AUTOSAR XML (schema 4-3-0)
package /DBCImport/CANTP
  can tp config CanTpConfig_LOCALCAN: communication-cluster=LOCALCAN, can-tp-ecu=SCM
    can tp channel CanTpChannel1: channel-id=1, channel-mode=HALF-DUPLEX-MODE
    tp-connections:
      addressing-format=STANDARD, can-tp-channel=CanTpChannel1, data-pdu=NPdu_LOCALCAN_TP_BDC_C_WPC, flow-control-pdu=NPdu_LOCALCAN_TP_WPC_C_BDC, max-block-size=0, padding-activation=true, ta-type=PHYSICAL, tp-sdu=ISignalIPdu_LOCALCAN_TP_BDC_C_WPC
      addressing-format=STANDARD, can-tp-channel=CanTpChannel1, data-pdu=NPdu_LOCALCAN_TP_WPC_C_BDC, flow-control-pdu=NPdu_LOCALCAN_TP_BDC_C_WPC, max-block-size=0, padding-activation=true, ta-type=PHYSICAL, tp-sdu=ISignalIPdu_LOCALCAN_TP_WPC_C_BDC
    can tp node SCM: connector=Conn_SCM_LOCALCAN
package /DBCImport/SWCComposition
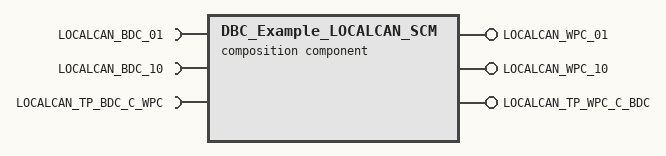
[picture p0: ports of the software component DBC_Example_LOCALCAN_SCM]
  composition sw component type DBC_Example_LOCALCAN_SCM
    provide port LOCALCAN_WPC_01: provided-interface=LOCALCAN_WPC_01
    provide port LOCALCAN_WPC_10: provided-interface=LOCALCAN_WPC_10
    provide port LOCALCAN_TP_WPC_C_BDC: provided-interface=LOCALCAN_TP_WPC_C_BDC
    require port LOCALCAN_BDC_01: required-interface=LOCALCAN_BDC_01
    require port LOCALCAN_BDC_10: required-interface=LOCALCAN_BDC_10
    require port LOCALCAN_TP_BDC_C_WPC: required-interface=LOCALCAN_TP_BDC_C_WPC
package /DBCImport/CLUSTERS
  can cluster LOCALCAN: baudrate=500000, protocol-name=CAN, speed=500
    can physical channel LOCALCAN: comm-connectors=Conn_SCM_LOCALCAN
      frame CanFrame_LOCALCAN_WPC_01: id 0x10, frame-length=8, can-addressing-mode=STANDARD, can-fd-frame-support=false  # [EC] On Event and On Change
        pdu ISignalIPdu_LOCALCAN_WPC_01: length=8, minimum-delay=0.02, transmission-mode-true-timing=event-controlled-timing={number-of-repetitions=3, repetition-period=0.04}
          signal ISignal_LOCALCAN_WPC_01_C_WPC_NFCReset: start 3, 1 bit, big-endian, init-value=0, base-type=boolean, compu {0=Default, 1=Reset Complete, phys=raw for raw 0}, transfer-property=TRIGGERED-ON-CHANGE  # NFC Deselect Result
          signal ISignal_LOCALCAN_WPC_01_C_WPC_NFCDetection: start 7, 2 bit, big-endian, init-value=0, base-type=uint8, compu {0=Off, 1=Detected, 2=Not Detected, phys=raw for raw 0..2}, transfer-property=TRIGGERED-ON-CHANGE  # Indicate NFC Device is detected or not
      frame CanFrame_LOCALCAN_BDC_01: id 0x11, frame-length=8, can-addressing-mode=STANDARD, can-fd-frame-support=false  # [EC] On Event and On Change
        pdu ISignalIPdu_LOCALCAN_BDC_01: length=8, minimum-delay=0.02, transmission-mode-true-timing=event-controlled-timing={number-of-repetitions=3, repetition-period=0.04}
          signal ISignal_LOCALCAN_BDC_01_C_WPCNFCcmd: start 5, 3 bit, big-endian, init-value=0, base-type=uint8, compu-method=ISignal_LOCALCAN_BDC_01_C_WPCNFCcmd, transfer-property=TRIGGERED-ON-CHANGE  # NFC Searchin Start/Stop command to WPC
          signal ISignal_LOCALCAN_BDC_01_C_BDCWPCNFCCmd: start 15, 2 bit, big-endian, init-value=0, base-type=uint8, compu-method=ISignal_LOCALCAN_BDC_01_C_BDCWPCNFCCmd, transfer-property=TRIGGERED-ON-CHANGE  # NFC Searchin Start/Stop command to WPC
      frame CanFrame_LOCALCAN_BDC_10: id 0x100, frame-length=8, can-addressing-mode=STANDARD, can-fd-frame-support=false  # [PE] Periodic and On Event
        pdu ISignalIPdu_LOCALCAN_BDC_10: length=8, minimum-delay=0.02, transmission-mode-true-timing={cyclic-timing={time-offset=0.04, time-period=0.2}, event-controlled-timing={number-of-repetitions=3, repetition-period=0.04}}
          signal ISignal_LOCALCAN_BDC_10_C_DeviceOnWPC: start 2, 2 bit, big-endian, init-value=0, base-type=uint8, compu-method=ISignal_LOCALCAN_BDC_10_C_DeviceOnWPC, transfer-property=TRIGGERED-ON-CHANGE  # Inform device on WPC
          signal ISignal_LOCALCAN_BDC_10_C_BDC_Status: start 7, 3 bit, big-endian, init-value=0, base-type=uint8, compu-method=ISignal_LOCALCAN_BDC_10_C_BDC_Status, transfer-property=TRIGGERED-ON-CHANGE  # BDC Processing Status
      frame CanFrame_LOCALCAN_WPC_10: id 0x110, frame-length=8, can-addressing-mode=STANDARD, can-fd-frame-support=false  # [PE] Periodic and On Event
        pdu ISignalIPdu_LOCALCAN_WPC_10: length=8, minimum-delay=0.02, transmission-mode-true-timing={cyclic-timing={time-offset=0.0, time-period=0.2}, event-controlled-timing={number-of-repetitions=3, repetition-period=0.04}}
          signal ISignal_LOCALCAN_WPC_10_C_WPC_Status: start 7, 3 bit, big-endian, init-value=0, base-type=uint8, compu-method=ISignal_LOCALCAN_WPC_10_C_WPC_Status, transfer-property=TRIGGERED-ON-CHANGE  # WPC Processing Status
          signal ISignal_LOCALCAN_WPC_10_C_WPCNFC_Option: start 15, 2 bit, big-endian, init-value=0, base-type=uint8, compu-method=ISignal_LOCALCAN_WPC_10_C_WPCNFC_Option, transfer-property=TRIGGERED-ON-CHANGE  # WPC NFC Option Applied Signal
      frame CanFrame_LOCALCAN_TP_BDC_C_WPC: id 0x30A, category=FULL_CAN, frame-length=8, can-addressing-mode=STANDARD, can-fd-frame-support=false  # [TP] TP Message
        pdu ISignalIPdu_LOCALCAN_TP_BDC_C_WPC: length=512, minimum-delay=0.02, transmission-mode-true-timing=event-controlled-timing={number-of-repetitions=3, repetition-period=0.04}
          signal ISignal_LOCALCAN_TP_BDC_C_WPC_LOCALCAN_TP_BDC_C_WPC_signal: start 0, 4096 bit, opaque, init-value=512 x 0, compu {phys=raw for raw 0}, implementation-data-type=array512uint8Dynamic, dynamic-length=true, transfer-property=PENDING  # TP From BDC to WPC
        n pdu NPdu_LOCALCAN_TP_BDC_C_WPC: length=8, meta-data-length=0
      frame CanFrame_LOCALCAN_TP_WPC_C_BDC: id 0x318, category=FULL_CAN, frame-length=8, can-addressing-mode=STANDARD, can-fd-frame-support=false  # [TP] TP Message
        pdu ISignalIPdu_LOCALCAN_TP_WPC_C_BDC: length=512, minimum-delay=0.02, transmission-mode-true-timing=event-controlled-timing={number-of-repetitions=3, repetition-period=0.04}
          signal ISignal_LOCALCAN_TP_WPC_C_BDC_LOCALCAN_TP_WPC_C_BDC_signal: start 0, 4096 bit, opaque, init-value=512 x 0, compu {phys=raw for raw 0}, implementation-data-type=array512uint8Dynamic, dynamic-length=true, transfer-property=TRIGGERED-WITHOUT-REPETITION  # TP From WPC to BDC
        n pdu NPdu_LOCALCAN_TP_WPC_C_BDC: length=8, meta-data-length=0
      frame CanFrame_LOCALCAN_NM_BDC: id 0x400, frame-length=8, can-addressing-mode=STANDARD, can-fd-frame-support=false
        user defined pdu UserDefinedPdu_LOCALCAN_NM_BDC: length=8, cdd-type=OsekNm
      frame CanFrame_LOCALCAN_NM_WPC: id 0x41E, frame-length=8, can-addressing-mode=STANDARD, can-fd-frame-support=false
        user defined pdu UserDefinedPdu_LOCALCAN_NM_WPC: length=8, cdd-type=OsekNm
      frame CanFrame_LOCALCAN_NM_ROA: id 0x449, frame-length=8, can-addressing-mode=STANDARD, can-fd-frame-support=false
        user defined pdu UserDefinedPdu_LOCALCAN_NM_ROA: length=8, cdd-type=OsekNm
      frame CanFrame_LOCALCAN_NM_DHL: id 0x460, frame-length=8, can-addressing-mode=STANDARD, can-fd-frame-support=false
        user defined pdu UserDefinedPdu_LOCALCAN_NM_DHL: length=8, cdd-type=OsekNm
      frame CanFrame_LOCALCAN_NM_DHR: id 0x461, frame-length=8, can-addressing-mode=STANDARD, can-fd-frame-support=false
        user defined pdu UserDefinedPdu_LOCALCAN_NM_DHR: length=8, cdd-type=OsekNm
      frame CanFrame_LOCALCAN_NM_Devtool: id 0x463, frame-length=8, can-addressing-mode=STANDARD, can-fd-frame-support=false
        user defined pdu UserDefinedPdu_LOCALCAN_NM_Devtool: length=8, cdd-type=OsekNm
      frame CanFrame_LOCALCAN_NM_UWB_FR: id 0x466, frame-length=8, can-addressing-mode=STANDARD, can-fd-frame-support=false
        user defined pdu UserDefinedPdu_LOCALCAN_NM_UWB_FR: length=8, cdd-type=OsekNm
      frame CanFrame_LOCALCAN_NM_UWB_FL: id 0x467, frame-length=8, can-addressing-mode=STANDARD, can-fd-frame-support=false
        user defined pdu UserDefinedPdu_LOCALCAN_NM_UWB_FL: length=8, cdd-type=OsekNm
      frame CanFrame_LOCALCAN_NM_UWB_RR: id 0x468, frame-length=8, can-addressing-mode=STANDARD, can-fd-frame-support=false
        user defined pdu UserDefinedPdu_LOCALCAN_NM_UWB_RR: length=8, cdd-type=OsekNm
      frame CanFrame_LOCALCAN_NM_UWB_RL: id 0x469, frame-length=8, can-addressing-mode=STANDARD, can-fd-frame-support=false
        user defined pdu UserDefinedPdu_LOCALCAN_NM_UWB_RL: length=8, cdd-type=OsekNm
      frame CanFrame_LOCALCAN_NM_UWB_TRNK: id 0x46D, frame-length=8, can-addressing-mode=STANDARD, can-fd-frame-support=false
        user defined pdu UserDefinedPdu_LOCALCAN_NM_UWB_TRNK: length=8, cdd-type=OsekNm
      frame CanFrame_LOCALCAN_NM_UWB_FRNK: id 0x46E, frame-length=8, can-addressing-mode=STANDARD, can-fd-frame-support=false
        user defined pdu UserDefinedPdu_LOCALCAN_NM_UWB_FRNK: length=8, cdd-type=OsekNm
      frame CanFrame_LOCALCAN_NM_UWB_BLE: id 0x474, frame-length=8, can-addressing-mode=STANDARD, can-fd-frame-support=false
        user defined pdu UserDefinedPdu_LOCALCAN_NM_UWB_BLE: length=8, cdd-type=OsekNm
      frame CanFrame_LOCALCAN_NM_UWB_INT: id 0x475, frame-length=8, can-addressing-mode=STANDARD, can-fd-frame-support=false
        user defined pdu UserDefinedPdu_LOCALCAN_NM_UWB_INT: length=8, cdd-type=OsekNm
package /DBCImport/COMPUMETHODS
  compu method ISignal_LOCALCAN_BDC_01_C_BDCWPCNFCCmd: 0=Default, 1=WPC NFC Polling (Search), 2=WPC NFC Deselect (Stop), 3=Invalid, phys=raw for raw 0
  compu method ISignal_LOCALCAN_BDC_01_C_WPCNFCcmd: 0=None, 1=NFC Searching On(HCE), 2=NFC Searching Off, 3=NFC Searching On(Usim), 4=reserved, 5=reserved, 6=reserved, 7=Invalid, phys=raw for raw 0..7
  compu method ISignal_LOCALCAN_BDC_10_C_BDC_Status: 0=Idle, 1=Process for WPC, 2=Process for DHL, 3=Process for DHR, 4=Process for BLE_TRX, 5=Process for DHRL, 6=Process for DHRR, 7=Process for UWB, phys=raw for raw 0..7
  compu method ISignal_LOCALCAN_BDC_10_C_DeviceOnWPC: 0=Not key device, 1=Phone key, 2=Card key, 3=Invaild, phys=raw for raw 0
  compu method ISignal_LOCALCAN_WPC_10_C_WPCNFC_Option: 0=Default(NotApplied), 1=Applied, 2=Reserved, 3=invalid, phys=raw for raw 0..3
  compu method ISignal_LOCALCAN_WPC_10_C_WPC_Status: 0=Off, 1=WPC Mode, 2=NFC Scanning, 3=NFC Communicating, 4=Reserved, 5=Reserved, 6=Reserved, 7=invalid, phys=raw for raw 0..7
package /DBCImport/IPDUGROUPS
  i signal i pdu group ISignalIPduGroupRx_SCM_LOCALCAN: communication-direction=IN, communication-mode=rx, i-signal-i-pdus=[ISignalIPdu_LOCALCAN_BDC_01, ISignalIPdu_LOCALCAN_BDC_10, ISignalIPdu_LOCALCAN_TP_BDC_C_WPC]
  i signal i pdu group ISignalIPduGroupTx_SCM_LOCALCAN: communication-direction=OUT, communication-mode=tx, i-signal-i-pdus=[ISignalIPdu_LOCALCAN_WPC_01, ISignalIPdu_LOCALCAN_WPC_10, ISignalIPdu_LOCALCAN_TP_WPC_C_BDC]
package /DBCImport/INTERFACES
  6 x sender receiver interface:
    LOCALCAN_BDC_01
      data C_WPCNFCcmd: base-type=uint8, compu-method=ISignal_LOCALCAN_BDC_01_C_WPCNFCcmd, type=uint8, init-value=0
      data C_BDCWPCNFCCmd: base-type=uint8, compu-method=ISignal_LOCALCAN_BDC_01_C_BDCWPCNFCCmd, type=uint8, init-value=0
    LOCALCAN_BDC_10
      data C_BDC_Status: base-type=uint8, compu-method=ISignal_LOCALCAN_BDC_10_C_BDC_Status, type=uint8, init-value=0
      data C_DeviceOnWPC: base-type=uint8, compu-method=ISignal_LOCALCAN_BDC_10_C_DeviceOnWPC, type=uint8, init-value=0
    LOCALCAN_TP_BDC_C_WPC
      data LOCALCAN_TP_BDC_C_WPC_signal: compu {phys=raw for raw 0}, sw-impl-policy=QUEUED, type=array512uint8Dynamic
    LOCALCAN_TP_WPC_C_BDC
      data LOCALCAN_TP_WPC_C_BDC_signal: compu {phys=raw for raw 0}, sw-impl-policy=QUEUED, type=array512uint8Dynamic
    LOCALCAN_WPC_01
      data C_WPC_NFCDetection: base-type=uint8, compu {0=Off, 1=Detected, 2=Not Detected, phys=raw for raw 0..2}, type=uint8, init-value=0
      data C_WPC_NFCReset: base-type=boolean, compu {0=Default, 1=Reset Complete, phys=raw for raw 0}, type=boolean, init-value=0
    LOCALCAN_WPC_10
      data C_WPC_Status: base-type=uint8, compu-method=ISignal_LOCALCAN_WPC_10_C_WPC_Status, type=uint8, init-value=0
      data C_WPCNFC_Option: base-type=uint8, compu-method=ISignal_LOCALCAN_WPC_10_C_WPCNFC_Option, type=uint8, init-value=0
package /DBCImport/ImplementationDataTypes_LOCALCAN
  impl type array512uint8Dynamic: category=ARRAY
    element uint8: array-size=512, array-size-semantics=VARIABLE-SIZE, implementation-data-type=uint8
